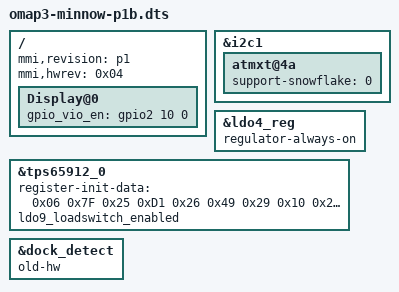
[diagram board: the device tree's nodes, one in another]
/*
 * Copyright (C) 2014 Motorola Mobility LLC
 *
 * This program is free software; you can redistribute it and/or modify
 * it under the terms of the GNU General Public License version 2 as
 * published by the Free Software Foundation.
 */
/dts-v1/;

/include/ "omap3-minnow.dtsi"

/ {
	mmi,revision = "p1";
	mmi,hwrev = <
		0x04   /* Minnow P1B portable */
	>;

	Display@0 {
		gpio_vio_en = <&gpio2 10 0>;    /* VDDIO gpio-42 */
	};

};

&i2c1 {
	atmxt@4a {
		support-snowflake = <0>;
	};
};

&ldo4_reg {
	regulator-always-on;
};

&tps65912_0 {
		register-init-data = <
                        0x06 0x7F /* DCDC1_LIMIT: 0.7V-1.4875V in 12.5mV steps */
			0x25 0xD1 /* DEVCTRL2: enable SLEEP, INT push/pull
					       200us TSLOT, INT active high */
			0x26 0x49 /* I2C_SPI_CFG: AVS ADDR = 0x13,
					DCDC1, DCDC4 is AVS ctrl */
			0x29 0x10 /* SET_OFF1: LDO5 */
			0x2A 0x24 /* SET_OFF2: DCDC1, DCDC4 */
			0x2d 0x88 /* DISCHARGE1: Enable LDO4, LDO8 */
			0x17 0xC0 /* LDO3_AVS b6=1 : ECO mode */
			0x1f 0xf8 /* LDO8: b6=1 : ECO mode */
			0x21 0xf2 /* LD10: b6=1 : ECO mode */
		>;
		ldo9_loadswitch_enabled;
};

&dock_detect {
	old-hw;
};
